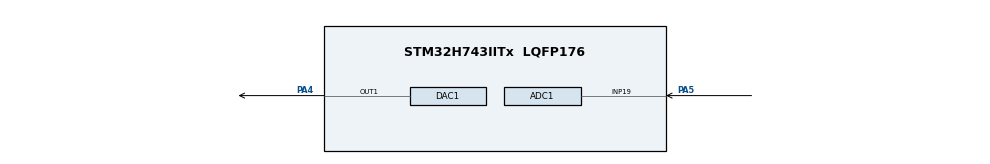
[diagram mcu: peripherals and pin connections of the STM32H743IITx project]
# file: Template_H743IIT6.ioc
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ADC1.Channel-0\#ChannelRegularConversion=ADC_CHANNEL_19
ADC1.ClockPrescaler=ADC_CLOCK_SYNC_PCLK_DIV4
ADC1.ContinuousConvMode=ENABLE
ADC1.ConversionDataManagement=ADC_CONVERSIONDATA_DMA_CIRCULAR
ADC1.ExternalTrigConv=ADC_SOFTWARE_START
ADC1.NbrOfConversion=1
ADC1.NbrOfConversionFlag=1
ADC1.OffsetNumber-0\#ChannelRegularConversion=ADC_OFFSET_NONE
ADC1.OffsetSignedSaturation-0\#ChannelRegularConversion=DISABLE
ADC1.Overrun=ADC_OVR_DATA_OVERWRITTEN
ADC1.OversamplingMode=DISABLE
ADC1.Rank-0\#ChannelRegularConversion=1
ADC1.Resolution=ADC_RESOLUTION_12B
ADC1.SamplingTime-0\#ChannelRegularConversion=ADC_SAMPLETIME_387CYCLES_5
ADC1.master=1
CORTEX_M7.AccessPermission-Cortex_Memory_Protection_Unit_Region0_Settings=MPU_REGION_FULL_ACCESS
CORTEX_M7.BaseAddress-Cortex_Memory_Protection_Unit_Region0_Settings=0x38000000
CORTEX_M7.CPU_DCache=Enabled
CORTEX_M7.CPU_ICache=Enabled
CORTEX_M7.Enable-Cortex_Memory_Protection_Unit_Region0_Settings=MPU_REGION_ENABLE
CORTEX_M7.IsCacheable-Cortex_Memory_Protection_Unit_Region0_Settings=MPU_ACCESS_CACHEABLE
CORTEX_M7.MPU_Control=MPU_PRIVILEGED_DEFAULT
CORTEX_M7.Size-Cortex_Memory_Protection_Unit_Region0_Settings=MPU_REGION_SIZE_64KB
DAC1.DAC_Channel-DAC_OUT1=DAC_CHANNEL_1
DAC1.DAC_Trigger-DAC_OUT1=DAC_TRIGGER_LPTIM1_OUT
DAC1.WaveGeneration-DAC_OUT1=DISABLE
Dma.ADC1.0.Direction=DMA_PERIPH_TO_MEMORY
Dma.ADC1.0.EventEnable=DISABLE
Dma.ADC1.0.FIFOMode=DMA_FIFOMODE_DISABLE
Dma.ADC1.0.Instance=DMA1_Stream0
Dma.ADC1.0.MemDataAlignment=DMA_MDATAALIGN_WORD
Dma.ADC1.0.MemInc=DMA_MINC_ENABLE
Dma.ADC1.0.Mode=DMA_CIRCULAR
Dma.ADC1.0.PeriphDataAlignment=DMA_PDATAALIGN_WORD
Dma.ADC1.0.PeriphInc=DMA_PINC_DISABLE
Dma.ADC1.0.Polarity=HAL_DMAMUX_REQ_GEN_RISING
Dma.ADC1.0.Priority=DMA_PRIORITY_LOW
Dma.ADC1.0.RequestNumber=1
Dma.ADC1.0.SignalID=NONE
Dma.ADC1.0.SyncEnable=ENABLE
Dma.ADC1.0.SyncPolarity=HAL_DMAMUX_SYNC_RISING
Dma.ADC1.0.SyncRequestNumber=1
Dma.ADC1.0.SyncSignalID=HAL_DMAMUX1_SYNC_LPTIM1_OUT
Dma.DAC1_CH1.1.Direction=DMA_MEMORY_TO_PERIPH
Dma.DAC1_CH1.1.EventEnable=DISABLE
Dma.DAC1_CH1.1.FIFOMode=DMA_FIFOMODE_DISABLE
Dma.DAC1_CH1.1.Instance=DMA1_Stream1
Dma.DAC1_CH1.1.MemDataAlignment=DMA_MDATAALIGN_WORD
Dma.DAC1_CH1.1.MemInc=DMA_MINC_ENABLE
Dma.DAC1_CH1.1.Mode=DMA_CIRCULAR
Dma.DAC1_CH1.1.PeriphDataAlignment=DMA_PDATAALIGN_WORD
Dma.DAC1_CH1.1.PeriphInc=DMA_PINC_DISABLE
Dma.DAC1_CH1.1.Polarity=HAL_DMAMUX_REQ_GEN_RISING
Dma.DAC1_CH1.1.Priority=DMA_PRIORITY_LOW
Dma.DAC1_CH1.1.RequestNumber=1
Dma.DAC1_CH1.1.SignalID=NONE
Dma.DAC1_CH1.1.SyncEnable=ENABLE
Dma.DAC1_CH1.1.SyncPolarity=HAL_DMAMUX_SYNC_RISING
Dma.DAC1_CH1.1.SyncRequestNumber=1
Dma.DAC1_CH1.1.SyncSignalID=HAL_DMAMUX1_SYNC_LPTIM1_OUT
Dma.Request0=ADC1
Dma.Request1=DAC1_CH1
LPTIM1.ClockPrescaler=LPTIM_PRESCALER_DIV64
Mcu.Family=STM32H7
Mcu.Name=STM32H743IITx
Mcu.Package=LQFP176
NVIC.ADC_IRQn=true\:0\:0\:false\:false\:true\:true\:true\:true
NVIC.DMA1_Stream0_IRQn=true\:0\:0\:false\:false\:true\:false\:true\:true
NVIC.DMA1_Stream1_IRQn=true\:0\:0\:false\:false\:true\:false\:true\:true
NVIC.DMAMUX1_OVR_IRQn=true\:0\:0\:false\:false\:true\:false\:true\:true
NVIC.PriorityGroup=NVIC_PRIORITYGROUP_4
PA13\ (JTMS/SWDIO).Mode=Serial_Wire
PA13\ (JTMS/SWDIO).Signal=DEBUG_JTMS-SWDIO
PA14\ (JTCK/SWCLK).Mode=Serial_Wire
PA14\ (JTCK/SWCLK).Signal=DEBUG_JTCK-SWCLK
PA4.Signal=COMP_DAC11_group
PA5.Signal=ADCx_INP19
PH0-OSC_IN\ (PH0).Mode=HSE-External-Oscillator
PH0-OSC_IN\ (PH0).Signal=RCC_OSC_IN
PH1-OSC_OUT\ (PH1).Mode=HSE-External-Oscillator
PH1-OSC_OUT\ (PH1).Signal=RCC_OSC_OUT
ProjectManager.HeapSize=0x200
ProjectManager.StackSize=0x400
ProjectManager.TargetToolchain=MDK-ARM V5
RCC.ADCFreq_Value=150000000
RCC.APB1Freq_Value=120000000
RCC.APB2Freq_Value=120000000
RCC.APB3Freq_Value=120000000
RCC.APB4Freq_Value=120000000
RCC.CortexFreq_Value=480000000
RCC.D1PPRE=RCC_APB3_DIV2
RCC.D2PPRE1=RCC_APB1_DIV2
RCC.D2PPRE2=RCC_APB2_DIV2
RCC.D3PPRE=RCC_APB4_DIV2
RCC.DIVM1=5
RCC.DIVM2=2
RCC.DIVN1=192
RCC.DIVN2=12
RCC.DIVP2=1
RCC.EnbaleCSS=true
RCC.HCLKFreq_Value=240000000
RCC.HPRE=RCC_HCLK_DIV2
RCC.PLL2FRACN=0
RCC.PLL3FRACN=0
RCC.PLLFRACN=0
RCC.PLLSourceVirtual=RCC_PLLSOURCE_HSE
RCC.PWR_Regulator_Voltage_Scale=PWR_REGULATOR_VOLTAGE_SCALE0
RCC.SYSCLKFreq_VALUE=480000000
RCC.SYSCLKSource=RCC_SYSCLKSOURCE_PLLCLK
RCC.USBFreq_Value=480000000
SH.ADCx_INP19.0=ADC1_INP19,IN19-Single-Ended
SH.COMP_DAC11_group.0=DAC1_OUT1,DAC_OUT1
TIM1.AutoReloadPreload=TIM_AUTORELOAD_PRELOAD_ENABLE
TIM1.Period=5
TIM1.Prescaler=9
TIM1.TIM_MasterOutputTrigger=TIM_TRGO_UPDATE
VP_LPTIM1_VS_LPTIM_counterModeInternalClock.Mode=Counts__internal_clock_event_00
VP_TIM1_VS_ClockSourceINT.Mode=Internal
board=custom

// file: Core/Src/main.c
/* USER CODE BEGIN Header */
/**
  ******************************************************************************
  * @file           : main.c
  * @brief          : Main program body
  ******************************************************************************
  * @attention
  *
  * Copyright (c) 2023 STMicroelectronics.
  * All rights reserved.
  *
  * This software is licensed under terms that can be found in the LICENSE file
  * in the root directory of this software component.
  * If no LICENSE file comes with this software, it is provided AS-IS.
  *
  ******************************************************************************
  */
/* USER CODE END Header */
#include "main.h"
#include "adc.h"
#include "dac.h"
#include "dma.h"
#include "lptim.h"
#include "tim.h"
#include "gpio.h"

/* USER CODE BEGIN Includes */
#include "arm_math.h"
/* USER CODE END Includes */

/* USER CODE BEGIN PV */
ALIGN_32BYTES(__attribute__((section(".RAM_D3"))) uint32_t val);
float32_t thd;
/* USER CODE END PV */

void SystemClock_Config(void);
static void MPU_Config(void);

int main(void)
{

  /* MPU Configuration--------------------------------------------------------*/
  MPU_Config();

  /* Enable I-Cache---------------------------------------------------------*/
  SCB_EnableICache();

  /* Enable D-Cache---------------------------------------------------------*/
  SCB_EnableDCache();

  /* MCU Configuration--------------------------------------------------------*/

  /* Reset of all peripherals, Initializes the Flash interface and the Systick. */
  HAL_Init();

  /* Configure the system clock */
  SystemClock_Config();

  /* Initialize all configured peripherals */
  MX_GPIO_Init();
  MX_ADC1_Init();
  MX_DAC1_Init();
  MX_DMA_Init();
  MX_TIM1_Init();
  MX_LPTIM1_Init();
  /* USER CODE BEGIN 2 */
	HAL_ADCEx_Calibration_Start(&hadc1, ADC_CALIB_OFFSET, ADC_SINGLE_ENDED);
	//HAL_ADC_Start_IT(&hadc1);
	HAL_ADC_Start_DMA(&hadc1, &val, 1);
	HAL_DAC_Start(&hdac1, DAC_CHANNEL_1);
	HAL_LPTIM_Counter_Start(&hlptim1, 60);
  /* USER CODE END 2 */

  /* Infinite loop */
  while (1)
  {

  }
}

void SystemClock_Config(void)
{
  RCC_OscInitTypeDef RCC_OscInitStruct = {0};
  RCC_ClkInitTypeDef RCC_ClkInitStruct = {0};

  /** Supply configuration update enable
  */
  HAL_PWREx_ConfigSupply(PWR_LDO_SUPPLY);

  /** Configure the main internal regulator output voltage
  */
  __HAL_PWR_VOLTAGESCALING_CONFIG(PWR_REGULATOR_VOLTAGE_SCALE1);

  while(!__HAL_PWR_GET_FLAG(PWR_FLAG_VOSRDY)) {}

  __HAL_RCC_SYSCFG_CLK_ENABLE();
  __HAL_PWR_VOLTAGESCALING_CONFIG(PWR_REGULATOR_VOLTAGE_SCALE0);

  while(!__HAL_PWR_GET_FLAG(PWR_FLAG_VOSRDY)) {}

  /** Macro to configure the PLL clock source
  */
  __HAL_RCC_PLL_PLLSOURCE_CONFIG(RCC_PLLSOURCE_HSE);

  /** Initializes the RCC Oscillators according to the specified parameters
  * in the RCC_OscInitTypeDef structure.
  */
  RCC_OscInitStruct.OscillatorType = RCC_OSCILLATORTYPE_HSE;
  RCC_OscInitStruct.HSEState = RCC_HSE_ON;
  RCC_OscInitStruct.PLL.PLLState = RCC_PLL_ON;
  RCC_OscInitStruct.PLL.PLLSource = RCC_PLLSOURCE_HSE;
  RCC_OscInitStruct.PLL.PLLM = 5;
  RCC_OscInitStruct.PLL.PLLN = 192;
  RCC_OscInitStruct.PLL.PLLP = 2;
  RCC_OscInitStruct.PLL.PLLQ = 2;
  RCC_OscInitStruct.PLL.PLLR = 2;
  RCC_OscInitStruct.PLL.PLLRGE = RCC_PLL1VCIRANGE_2;
  RCC_OscInitStruct.PLL.PLLVCOSEL = RCC_PLL1VCOWIDE;
  RCC_OscInitStruct.PLL.PLLFRACN = 0;
  if (HAL_RCC_OscConfig(&RCC_OscInitStruct) != HAL_OK)
  {
    Error_Handler();
  }

  /** Initializes the CPU, AHB and APB buses clocks
  */
  RCC_ClkInitStruct.ClockType = RCC_CLOCKTYPE_HCLK|RCC_CLOCKTYPE_SYSCLK
                              |RCC_CLOCKTYPE_PCLK1|RCC_CLOCKTYPE_PCLK2
                              |RCC_CLOCKTYPE_D3PCLK1|RCC_CLOCKTYPE_D1PCLK1;
  RCC_ClkInitStruct.SYSCLKSource = RCC_SYSCLKSOURCE_PLLCLK;
  RCC_ClkInitStruct.SYSCLKDivider = RCC_SYSCLK_DIV1;
  RCC_ClkInitStruct.AHBCLKDivider = RCC_HCLK_DIV2;
  RCC_ClkInitStruct.APB3CLKDivider = RCC_APB3_DIV2;
  RCC_ClkInitStruct.APB1CLKDivider = RCC_APB1_DIV2;
  RCC_ClkInitStruct.APB2CLKDivider = RCC_APB2_DIV2;
  RCC_ClkInitStruct.APB4CLKDivider = RCC_APB4_DIV2;

  if (HAL_RCC_ClockConfig(&RCC_ClkInitStruct, FLASH_LATENCY_4) != HAL_OK)
  {
    Error_Handler();
  }

  /** Enables the Clock Security System
  */
  HAL_RCC_EnableCSS();
}

/* USER CODE BEGIN 4 */
//void HAL_ADC_ConvCpltCallback(ADC_HandleTypeDef *hadc) {
//	if(hadc->Instance == ADC1) {
//		//__ASM("BKPT 0xAB");
//		//val = HAL_ADC_GetValue(&hadc1);
//		HAL_DAC_SetValue(&hdac1, DAC_CHANNEL_1, DAC_ALIGN_12B_R, val);
//		HAL_DAC_Start(&hdac1, DAC_CHANNEL_1);
//		//HAL_ADC_Start_IT(&hadc1);
//		HAL_ADC_Start_DMA(&hadc1, &val, 1);
//	}
//}
/* USER CODE END 4 */

/* MPU Configuration */

void MPU_Config(void)
{
  MPU_Region_InitTypeDef MPU_InitStruct = {0};

  /* Disables the MPU */
  HAL_MPU_Disable();

  /** Initializes and configures the Region and the memory to be protected
  */
  MPU_InitStruct.Enable = MPU_REGION_ENABLE;
  MPU_InitStruct.Number = MPU_REGION_NUMBER0;
  MPU_InitStruct.BaseAddress = 0x38000000;
  MPU_InitStruct.Size = MPU_REGION_SIZE_64KB;
  MPU_InitStruct.SubRegionDisable = 0x0;
  MPU_InitStruct.TypeExtField = MPU_TEX_LEVEL0;
  MPU_InitStruct.AccessPermission = MPU_REGION_FULL_ACCESS;
  MPU_InitStruct.DisableExec = MPU_INSTRUCTION_ACCESS_ENABLE;
  MPU_InitStruct.IsShareable = MPU_ACCESS_NOT_SHAREABLE;
  MPU_InitStruct.IsCacheable = MPU_ACCESS_CACHEABLE;
  MPU_InitStruct.IsBufferable = MPU_ACCESS_NOT_BUFFERABLE;

  HAL_MPU_ConfigRegion(&MPU_InitStruct);
  /* Enables the MPU */
  HAL_MPU_Enable(MPU_PRIVILEGED_DEFAULT);

}

void Error_Handler(void)
{
  __disable_irq();
  while (1)
  {
  }
}
